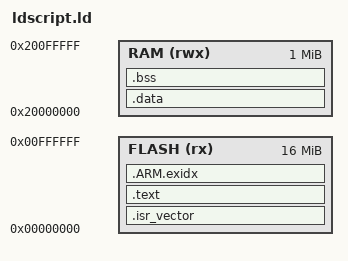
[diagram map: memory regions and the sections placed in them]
ENTRY(Reset_Handler)

MEMORY
{
  FLASH (rx) : ORIGIN = 0x00000000, LENGTH = 16M
  RAM (rwx)  : ORIGIN = 0x20000000, LENGTH = 1M
}

_estack = ORIGIN(RAM) + LENGTH(RAM);

SECTIONS
{
  .isr_vector :
  {
    KEEP(*(.isr_vector))
  } > FLASH

  .text :
  {
    *(.text*)
    *(.rodata*)
    KEEP(*(.init))
    KEEP(*(.fini))
  } > FLASH

  .ARM.exidx :
  {
    __exidx_start = .;
    *(.ARM.exidx*)
    __exidx_end = .;
  } > FLASH

  _sidata = LOADADDR(.data);
  .data : AT(ADDR(.ARM.exidx) + SIZEOF(.ARM.exidx))
  {
    _sdata = .;
    *(.data*)
    _edata = .;
  } > RAM

  .bss (NOLOAD) :
  {
    _sbss = .;
    *(.bss*)
    *(COMMON)
    _ebss = .;
  } > RAM

  _end = .;
  end = .;
  __end__ = .;
}
